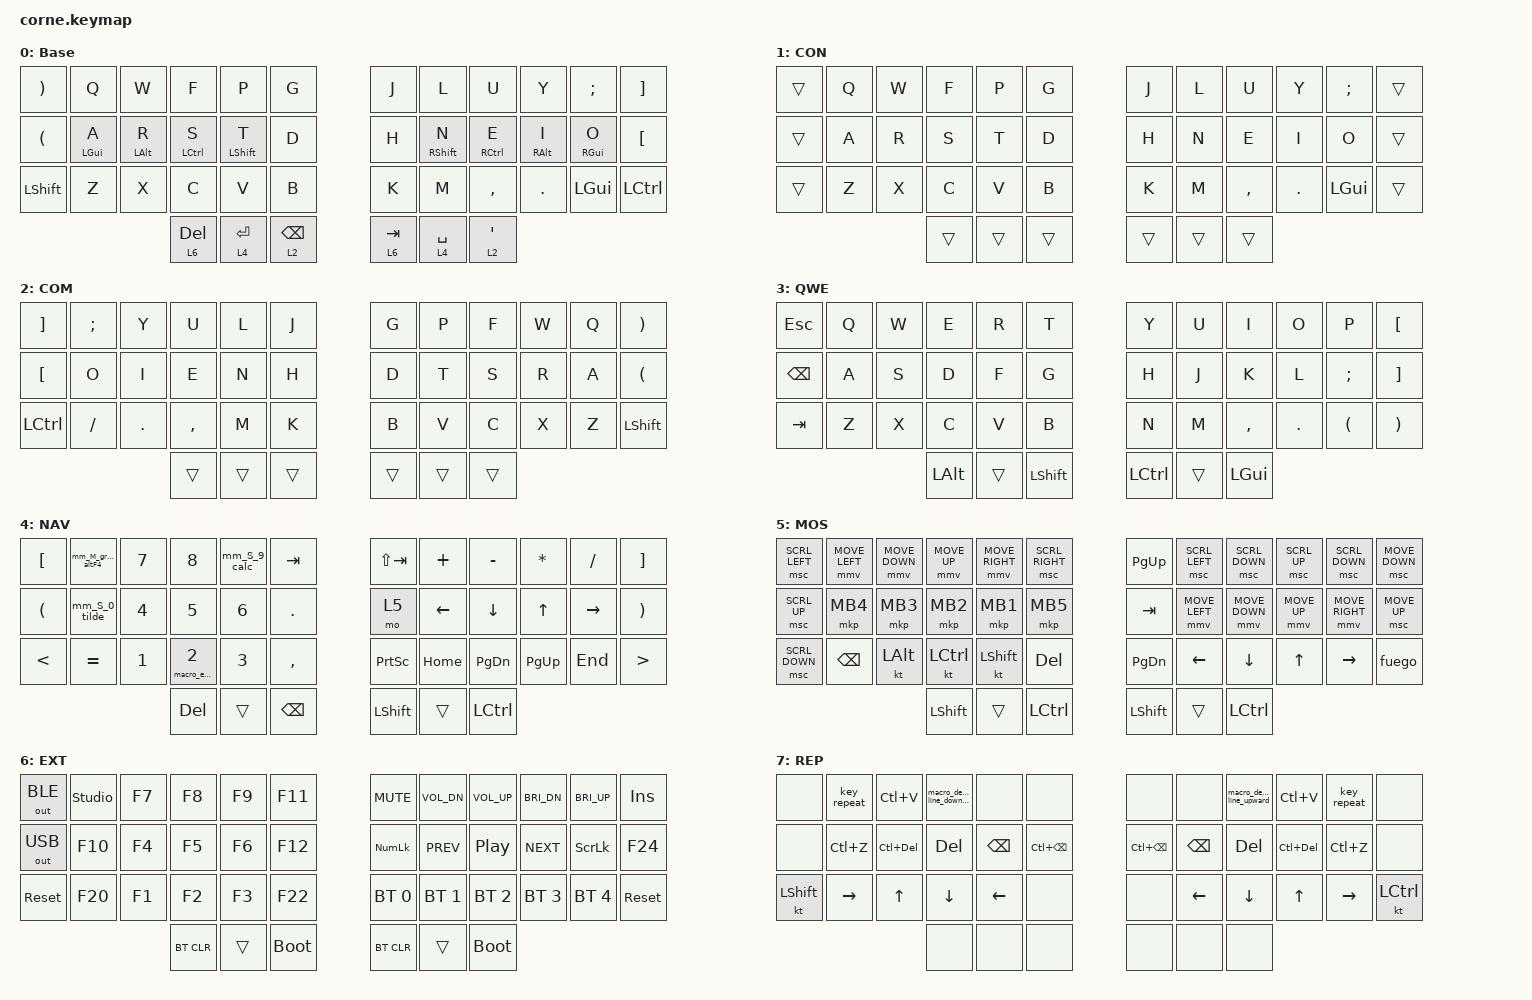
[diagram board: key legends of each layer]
/*
 * Copyright (c) 2020 The ZMK Contributors
 *
 * SPDX-License-Identifier: MIT
 */

#include "mouse.dtsi"
#include <behaviors.dtsi>
#include <dt-bindings/zmk/bt.h>
#include <dt-bindings/zmk/keys.h>
#include <dt-bindings/zmk/outputs.h>
#include <dt-bindings/led/led.h>
#include <dt-bindings/zmk/reset.h>

&caps_word { continue-list = <UNDERSCORE BACKSPACE DELETE LEFT RIGHT UP DOWN MINUS>; };

&lt {
    quick-tap-ms = <170>;
    require-prior-idle-ms = <150>;
};

&sk {
    release-after-ms = <1500>;
    quick-release;
};

&sl { release-after-ms = <500>; };

/ {
    behaviors {
        ht_kp_kp: ht_kp_kp {
            compatible = "zmk,behavior-hold-tap";
            label = "HT | KP / KP";
            bindings = <&kp>, <&kp>;

            #binding-cells = <2>;
            tapping-term-ms = <300>;
            flavor = "tap-preferred";
            quick-tap-ms = <170>;
        };

        td_S_CS: td_S_CS {
            compatible = "zmk,behavior-tap-dance";
            label = "TD | S / CS";
            #binding-cells = <0>;
            bindings = <&kp LSHFT>, <&kp LC(LSHIFT)>;
        };

        td_C_CA: td_C_CA {
            compatible = "zmk,behavior-tap-dance";
            label = "TD | C / CA";
            #binding-cells = <0>;
            bindings = <&kp LCTRL>, <&kp LC(LALT)>;
        };

        ht_capw: ht_capw {
            compatible = "zmk,behavior-hold-tap";
            label = "HT | CAPW";
            bindings = <&kp>, <&caps_word>;

            #binding-cells = <2>;
            tapping-term-ms = <170>;
        };

        ht170_kp_kp: ht170_kp_kp {
            compatible = "zmk,behavior-hold-tap";
            label = "HT170 | KP / KP";
            bindings = <&kp>, <&kp>;

            #binding-cells = <2>;
            tapping-term-ms = <170>;
            quick-tap-ms = <100>;
        };

        fuego: fuego {
            compatible = "zmk,behavior-hold-tap";
            label = "FUEGO";
            bindings = <&macro_hyperheat>, <&macro_superhot>;

            #binding-cells = <2>;
            tapping-term-ms = <500>;
        };

        email_1: email_1 {
            compatible = "zmk,behavior-hold-tap";
            label = "EMAIL_1";
            bindings = <&macro_email_dd431>, <&kp>;

            #binding-cells = <2>;
            tapping-term-ms = <200>;
        };

        ht500_kp_kp: ht500_kp_kp {
            compatible = "zmk,behavior-hold-tap";
            label = "HT500 | KP / KP";
            bindings = <&kp>, <&kp>;

            #binding-cells = <2>;
            tapping-term-ms = <500>;
            flavor = "tap-preferred";
            quick-tap-ms = <200>;
        };

        mm_A_volUp_briUp: mm_A_volUp_briUp {
            compatible = "zmk,behavior-mod-morph";
            label = "MM / ALT | VOL_UP / BRI_UP";
            bindings = <&kp C_VOL_UP>, <&kp C_BRI_UP>;

            #binding-cells = <0>;
            mods = <(MOD_LALT|MOD_RALT)>;
        };

        mm_A_volDn_briDn: mm_A_volDn_briDn {
            compatible = "zmk,behavior-mod-morph";
            label = "MM / ALT | VOLDN / BRIDN";
            bindings = <&ht_kp_kp C_MUTE C_VOL_DN>, <&kp C_BRI_DN>;

            #binding-cells = <0>;
            mods = <(MOD_LALT|MOD_RALT)>;
        };

        ht_mo_sl: ht_mo_sl {
            compatible = "zmk,behavior-hold-tap";
            label = "HT | MO / SL";
            bindings = <&mo>, <&sl>;

            #binding-cells = <2>;
            tapping-term-ms = <200>;
            flavor = "tap-preferred";
        };

        mm_S_0_tilde: mm_S_0_tilde {
            compatible = "zmk,behavior-mod-morph";
            label = "MM_S_0_TILDE";
            bindings = <&kp N0>, <&kp TILDE>;

            #binding-cells = <0>;
            mods = <(MOD_LSFT|MOD_RSFT)>;
        };

        mm_S_kp1_1: mm_S_kp1_1 {
            compatible = "zmk,behavior-mod-morph";
            label = "MM_S_KP1_1";
            bindings = <&kp KP_N1>, <&kp LS(N1)>;

            #binding-cells = <0>;
            mods = <(MOD_LSFT|MOD_RSFT)>;
        };

        mm_S_kp2_2: mm_S_kp2_2 {
            compatible = "zmk,behavior-mod-morph";
            label = "MM_S_KP2_2";
            bindings = <&kp KP_N2>, <&kp LS(N2)>;

            #binding-cells = <0>;
            mods = <(MOD_LSFT|MOD_RSFT)>;
        };

        mm_S_kp3_3: mm_S_kp3_3 {
            compatible = "zmk,behavior-mod-morph";
            label = "MM_S_KP3_3";
            bindings = <&kp KP_N3>, <&kp LS(N3)>;

            #binding-cells = <0>;
            mods = <(MOD_LSFT|MOD_RSFT)>;
        };

        mm_S_kp4_4: mm_S_kp4_4 {
            compatible = "zmk,behavior-mod-morph";
            label = "MM_S_KP4_4";
            bindings = <&kp KP_N4>, <&kp LS(N4)>;

            #binding-cells = <0>;
            mods = <(MOD_LSFT|MOD_RSFT)>;
        };

        mm_S_kp5_5: mm_S_kp5_5 {
            compatible = "zmk,behavior-mod-morph";
            label = "MM_S_KP5_5";
            bindings = <&kp KP_N5>, <&kp LS(N5)>;

            #binding-cells = <0>;
            mods = <(MOD_LSFT|MOD_RSFT)>;
        };

        mm_S_kp6_6: mm_S_kp6_6 {
            compatible = "zmk,behavior-mod-morph";
            label = "MM_S_KP6_6";
            bindings = <&kp KP_N6>, <&kp LS(N6)>;

            #binding-cells = <0>;
            mods = <(MOD_LSFT|MOD_RSFT)>;
        };

        mm_S_kp7_7: mm_S_kp7_7 {
            compatible = "zmk,behavior-mod-morph";
            label = "MM_S_KP7_7";
            bindings = <&kp KP_N7>, <&kp LS(N7)>;

            #binding-cells = <0>;
            mods = <(MOD_LSFT|MOD_RSFT)>;
        };

        mm_S_kp8_8: mm_S_kp8_8 {
            compatible = "zmk,behavior-mod-morph";
            label = "MM_S_KP8_8";
            bindings = <&kp KP_N8>, <&kp LS(N8)>;

            #binding-cells = <0>;
            mods = <(MOD_LSFT|MOD_RSFT)>;
        };

        mm_S_9_calc: mm_S_9_calc {
            compatible = "zmk,behavior-mod-morph";
            label = "MM_S_9_CALC";
            bindings = <&kp N9>, <&kp K_CALC>;

            #binding-cells = <0>;
            mods = <(MOD_LSFT|MOD_RSFT)>;
        };

        hrm_r: hrm_r {
            compatible = "zmk,behavior-hold-tap";
            label = "HRM_R";
            bindings = <&kp>, <&kp>;

            #binding-cells = <2>;
            tapping-term-ms = <1000>;
            quick-tap-ms = <80>;
            require-prior-idle-ms = <80>;
            flavor = "balanced";
            hold-trigger-on-release;
            hold-trigger-key-positions = <0 1 2 3 4 5 12 13 14 15 16 17 24 25 26 27 28 29 36 37 38 39 41 11 23 35>;
        };

        hrm_l: hrm_l {
            compatible = "zmk,behavior-hold-tap";
            label = "HRM_L";
            bindings = <&kp>, <&kp>;

            #binding-cells = <2>;
            tapping-term-ms = <1000>;
            quick-tap-ms = <80>;
            require-prior-idle-ms = <80>;
            flavor = "balanced";
            hold-trigger-on-release;
            hold-trigger-key-positions = <6 7 8 9 10 11 18 19 20 21 22 23 30 31 32 33 34 35 39 40 41 0 12 24 36 38>;
        };

        mm_S_lt_gt: mm_S_lt_gt {
            compatible = "zmk,behavior-mod-morph";
            label = "MM / SHF | LT / GT";
            bindings = <&kp LT>, <&kp GT>;

            #binding-cells = <0>;
            mods = <(MOD_LSFT|MOD_RSFT)>;
        };

        td_shf_moBaseMir: td_shf_moBaseMir {
            compatible = "zmk,behavior-tap-dance";
            label = "TD_SHF_MOBASEMIR";
            #binding-cells = <0>;
            bindings = <&kp LSHFT>, <&mo 0>;

            tapping-term-ms = <150>;
        };

        td_ctr_moBaseMir: td_ctr_moBaseMir {
            compatible = "zmk,behavior-tap-dance";
            label = "TD_CTR_MOBASEMIR";
            #binding-cells = <0>;
            bindings = <&kp LCTRL>, <&mo 0>;

            tapping-term-ms = <150>;
        };

        ht170_mo_mmbspc: ht170_mo_mmbspc {
            compatible = "zmk,behavior-hold-tap";
            label = "HT170_MO_MMBSPC";
            bindings = <&mo>, <&none>;

            #binding-cells = <2>;
            tapping-term-ms = <170>;
            quick-tap-ms = <120>;
            flavor = "hold-preferred";
        };

        td_pgdn_pgup: td_pgdn_pgup {
            compatible = "zmk,behavior-tap-dance";
            label = "TD_PGDN_PGUP";
            #binding-cells = <0>;
            bindings = <&kp PG_DN>, <&kp PG_UP>;

            tapping-term-ms = <120>;
        };

        td_pp_next_prev: td_pp_next_prev {
            compatible = "zmk,behavior-tap-dance";
            label = "TD_PP_NEXT_PREV";
            #binding-cells = <0>;
            bindings = <&kp C_PP>, <&kp C_NEXT>, <&kp C_PREV>;
        };

        mm_M_gresc_altF4: mm_M_gresc_altF4 {
            compatible = "zmk,behavior-mod-morph";
            label = "MM_M_GRESC_ALTF4";
            bindings = <&gresc>, <&kp LA(F4)>;

            #binding-cells = <0>;
            mods = <(MOD_LALT|MOD_RALT)>;
        };

        mm_S_bsp_del: mm_S_bsp_del {
            compatible = "zmk,behavior-mod-morph";
            label = "MM_S_BSP_DEL";
            bindings = <&kp BSPC>, <&kp DEL>;

            #binding-cells = <0>;
            mods = <(MOD_LSFT|MOD_RSFT)>;
        };

        ht_mo_mmLGbsp: ht_mo_mmLGbsp {
            compatible = "zmk,behavior-hold-tap";
            label = "HT_MO_MMLGBSP";
            bindings = <&mo>, <&mm_S_bsp_del>;

            #binding-cells = <2>;
            tapping-term-ms = <200>;
            quick-tap-ms = <200>;
            flavor = "hold-preferred";
        };

        ht_sl_kp: ht_sl_kp {
            compatible = "zmk,behavior-hold-tap";
            label = "HT_SL_KP";
            bindings = <&sl>, <&kp>;

            #binding-cells = <2>;
            tapping-term-ms = <200>;
            quick-tap-ms = <170>;
            flavor = "tap-preferred";
        };

        mm_S_lpar_rpar: mm_S_lpar_rpar {
            compatible = "zmk,behavior-mod-morph";
            label = "MM_S_LPAR_RPAR";
            bindings = <&kp LPAR>, <&kp RPAR>;

            #binding-cells = <0>;
            mods = <(MOD_LSFT|MOD_RSFT)>;
        };

        mm_S_lbkt_rbkt: mm_S_lbkt_rbkt {
            compatible = "zmk,behavior-mod-morph";
            label = "MM_S_LBKT_RBKT";
            bindings = <&kp LBKT>, <&kp RBKT>;

            #binding-cells = <0>;
            mods = <(MOD_LSFT|MOD_RSFT)>;
        };

        mm_S_lbrc_rbrc: mm_S_lbrc_rbrc {
            compatible = "zmk,behavior-mod-morph";
            label = "MM_S_LBRC_RBRC";
            bindings = <&kp LBRC>, <&kp RBRC>;

            #binding-cells = <0>;
            mods = <(MOD_LSFT|MOD_RSFT)>;
        };

        ht_parpair_brkpair: ht_parpair_brkpair {
            compatible = "zmk,behavior-hold-tap";
            label = "HT_PARPAIR_BRKPAIR";
            bindings = <&macro_paren_pair>, <&macro_bracket_pair>;

            #binding-cells = <2>;
            tapping-term-ms = <170>;
            flavor = "balanced";
        };

        ht_brcpair_pointypair: ht_brcpair_pointypair {
            compatible = "zmk,behavior-hold-tap";
            label = "HT_BRCPAIR_POINTYPAIR";
            bindings = <&macro_brace_pair>, <&macro_pointy_pair>;

            #binding-cells = <2>;
            tapping-term-ms = <170>;
            flavor = "balanced";
        };
    };

    macros {
        macro_superhot: superhot {
            compatible = "zmk,behavior-macro";
            #binding-cells = <0>;
            bindings = <&kp LS(I) &kp T &kp S &kp LS(D) &kp LS(M) &kp LS(D) &kp N2 &kp N5 &kp N1 &kp N0 &kp N1 &kp N5 &kp N0 &kp N7>;
            label = "SUPERHOT";
        };

        macro_hyperheat: hyperheat {
            compatible = "zmk,behavior-macro";
            #binding-cells = <0>;
            bindings = <&kp DLLR &kp LS(O) &kp LS(N) &kp D &kp LS(E) &kp LS(R) &kp LS(K) &kp LS(R) &kp AT &kp LS(F) &kp LS(T) &kp LS(F) &kp AT &kp LS(H) &kp LS(R) &kp LS(Z) &kp LS(E) &kp LS(U) &kp LS(G) &kp SPACE &kp N1 &kp N8 &kp N2>;
            label = "HYPERHEAT";
        };

        macro_email_dd431: email_dd431 {
            compatible = "zmk,behavior-macro";
            #binding-cells = <0>;
            bindings = <&kp D &kp U &kp C &kp DOT &kp D &kp A &kp O &kp DOT &kp N4 &kp N3 &kp N1 &kp AT &kp G &kp M &kp A &kp I &kp L &kp DOT &kp C &kp O &kp M>;
            label = "EMAIL_DD431";
        };

        macro_paren_pair: macro_paren_pair {
            compatible = "zmk,behavior-macro";
            #binding-cells = <0>;
            bindings = <&kp LPAR &kp RPAR &kp LEFT>;
            label = "MACRO_PAREN_PAIR";
        };

        macro_bracket_pair: macro_bracket_pair {
            compatible = "zmk,behavior-macro";
            #binding-cells = <0>;
            bindings = <&kp LBKT &kp RBKT &kp LEFT>;
            label = "MACRO_BRACKET_PAIR";
        };

        macro_brace_pair: macro_brace_pair {
            compatible = "zmk,behavior-macro";
            #binding-cells = <0>;
            bindings = <&kp LBRC &kp RBRC &kp LEFT>;
            label = "MACRO_BRACE_PAIR";
        };

        macro_pointy_pair: macro_pointy_pair {
            compatible = "zmk,behavior-macro";
            #binding-cells = <0>;
            bindings = <&kp LT &kp GT &kp LEFT>;
            label = "MACRO_POINTY_PAIR";
        };

        macro_delete_line_upward: macro_delete_line {
            compatible = "zmk,behavior-macro";
            #binding-cells = <0>;
            bindings = <&kp END &kp LS(HOME) &kp LS(UP) &kp LS(END) &kp BSPC>;
            label = "MACRO_DELETE_LINE";
        };

        macro_delete_line_downward: macro_delete_line_downward {
            compatible = "zmk,behavior-macro";
            #binding-cells = <0>;
            bindings = <&kp HOME &kp LS(END) &kp LS(DOWN) &kp LS(HOME) &kp BSPC>;
            label = "MACRO_DELETE_LINE_DOWNWARD";
        };
    };

    combos {
        compatible = "zmk,combos";

        combo_mo_mouse {
            bindings = <&mo 5>;
            key-positions = <37 40>;
            timeout-ms = <100>;
            require-prior-idle-ms = <170>;
        };

        combo_mo_deleter {
            bindings = <&mo 7>;
            key-positions = <38 39>;
            timeout-ms = <100>;
            require-prior-idle-ms = <170>;
        };

        combo_to_base {
            bindings = <&to 0>;
            key-positions = <4 3>;
            timeout-ms = <30>;
            require-prior-idle-ms = <200>;
        };

        combo_to_colemak {
            bindings = <&to 1>;
            key-positions = <4 2>;
            timeout-ms = <30>;
            require-prior-idle-ms = <200>;
        };

        combo_to_qwerty {
            bindings = <&to 3>;
            key-positions = <2 1>;
            timeout-ms = <30>;
            require-prior-idle-ms = <200>;
        };

        combo_to_mouse {
            bindings = <&to 5>;
            key-positions = <2 3>;
            timeout-ms = <30>;
            require-prior-idle-ms = <200>;
        };

        combo_to_navnum {
            bindings = <&to 4>;
            key-positions = <3 5>;
            timeout-ms = <30>;
            require-prior-idle-ms = <200>;
        };

        combo_to_extra {
            bindings = <&to 6>;
            key-positions = <5 4>;
            timeout-ms = <30>;
            require-prior-idle-ms = <200>;
        };

        combo_sk_C {
            bindings = <&sk LCTRL>;
            key-positions = <2 15>;
            timeout-ms = <30>;
            require-prior-idle-ms = <350>;
            layers = <0 1 4 5 6>;
            slow-release;
        };

        combo_sk_S {
            bindings = <&sk LSHFT>;
            key-positions = <3 16>;
            timeout-ms = <30>;
            require-prior-idle-ms = <350>;
            layers = <0 1 4 5 6>;
            slow-release;
        };

        combo_sk_M {
            bindings = <&sk LALT>;
            key-positions = <1 14>;
            timeout-ms = <30>;
            require-prior-idle-ms = <350>;
            layers = <0 1 4 5 6>;
            slow-release;
        };

        combo_sk_CS {
            bindings = <&sk LS(LCTRL)>;
            key-positions = <19 8>;
            timeout-ms = <30>;
            require-prior-idle-ms = <350>;
            layers = <0 1 4 5 6>;
            slow-release;
        };

        combo_sk_CM {
            bindings = <&sk LA(LCTRL)>;
            key-positions = <20 9>;
            timeout-ms = <30>;
            require-prior-idle-ms = <350>;
            layers = <0 1 4 5 6>;
            slow-release;
        };

        combo_sk_SM {
            bindings = <&sk LA(LSHFT)>;
            key-positions = <21 10>;
            timeout-ms = <30>;
            require-prior-idle-ms = <350>;
            layers = <0 1 4 5 6>;
            slow-release;
        };

        combo_bslh {
            bindings = <&kp BSLH>;
            key-positions = <16 29>;
            timeout-ms = <30>;
            slow-release;
            require-prior-idle-ms = <170>;
        };

        combo_under {
            bindings = <&kp UNDER>;
            key-positions = <15 28>;
            timeout-ms = <30>;
            slow-release;
            require-prior-idle-ms = <170>;
        };

        combo_lt {
            bindings = <&kp LT>;
            key-positions = <14 27>;
            timeout-ms = <30>;
            slow-release;
            require-prior-idle-ms = <170>;
        };

        combo_exclam {
            bindings = <&kp EXCL>;
            key-positions = <29 28>;
            timeout-ms = <30>;
            slow-release;
            require-prior-idle-ms = <170>;
        };

        combo_lpar {
            bindings = <&mm_S_lpar_rpar>;
            key-positions = <28 27>;
            timeout-ms = <50>;
            slow-release;
            require-prior-idle-ms = <170>;
        };

        combo_lbrc {
            bindings = <&mm_S_lbrc_rbrc>;
            key-positions = <27 26>;
            timeout-ms = <30>;
            slow-release;
            require-prior-idle-ms = <170>;
        };

        combo_lbkt {
            bindings = <&mm_S_lbkt_rbkt>;
            key-positions = <26 25>;
            timeout-ms = <30>;
            slow-release;
            require-prior-idle-ms = <170>;
        };

        combo_fslh {
            bindings = <&kp FSLH>;
            key-positions = <19 30>;
            timeout-ms = <30>;
            slow-release;
            require-prior-idle-ms = <170>;
        };

        combo_equal {
            bindings = <&kp EQUAL>;
            key-positions = <20 31>;
            timeout-ms = <30>;
            slow-release;
            require-prior-idle-ms = <170>;
        };

        combo_at {
            bindings = <&kp AT>;
            key-positions = <21 32>;
            timeout-ms = <30>;
            slow-release;
            require-prior-idle-ms = <170>;
        };

        combo_pipe {
            bindings = <&kp PIPE>;
            key-positions = <30 31>;
            timeout-ms = <30>;
            slow-release;
            require-prior-idle-ms = <170>;
        };

        combo_amps {
            bindings = <&kp AMPS>;
            key-positions = <31 32>;
            timeout-ms = <30>;
            slow-release;
            require-prior-idle-ms = <170>;
        };

        combo_hash {
            bindings = <&kp HASH>;
            key-positions = <32 33>;
            timeout-ms = <30>;
            slow-release;
            require-prior-idle-ms = <170>;
        };

        combo_qmark {
            bindings = <&kp QMARK>;
            key-positions = <33 34>;
            timeout-ms = <50>;
            slow-release;
            require-prior-idle-ms = <170>;
        };

        combo_paste {
            bindings = <&kp LC(V)>;
            key-positions = <28 27 26>;
            timeout-ms = <50>;
            slow-release;
            require-prior-idle-ms = <170>;
        };

        combo_copy {
            bindings = <&kp LC(C)>;
            key-positions = <27 26 25>;
            timeout-ms = <50>;
            slow-release;
            require-prior-idle-ms = <170>;
        };

        combo_cut {
            bindings = <&kp LC(X)>;
            key-positions = <26 25 24>;
            timeout-ms = <50>;
            slow-release;
            require-prior-idle-ms = <170>;
        };

        combo_space {
            bindings = <&kp SPACE>;
            key-positions = <16 17>;
            timeout-ms = <30>;
            require-prior-idle-ms = <200>;
        };

        combo_enter {
            bindings = <&kp ENTER>;
            key-positions = <19 18>;
            timeout-ms = <30>;
            require-prior-idle-ms = <200>;
        };

        combo_repeate_l {
            bindings = <&key_repeat>;
            key-positions = <17 4>;
            timeout-ms = <80>;
            require-prior-idle-ms = <200>;
        };

        combo_repeat_r {
            bindings = <&key_repeat>;
            key-positions = <18 7>;
            timeout-ms = <80>;
            require-prior-idle-ms = <200>;
        };

        combo_bsp {
            bindings = <&kp BSPC>;
            key-positions = <7 8>;
            timeout-ms = <50>;
            require-prior-idle-ms = <200>;
        };

        combo_del {
            bindings = <&kp DEL>;
            key-positions = <8 9>;
            timeout-ms = <50>;
            require-prior-idle-ms = <200>;
        };

        combo_C_bsp {
            bindings = <&kp LC(BSPC)>;
            key-positions = <7 6>;
            timeout-ms = <50>;
            require-prior-idle-ms = <200>;
        };

        combo_C_del {
            bindings = <&kp LC(DEL)>;
            key-positions = <10 9>;
            timeout-ms = <50>;
            require-prior-idle-ms = <200>;
        };

        combo_capsw {
            bindings = <&caps_word>;
            key-positions = <17 18>;
            timeout-ms = <80>;
            require-prior-idle-ms = <170>;
            slow-release;
        };

        combo_capsl {
            bindings = <&kp CAPS>;
            key-positions = <5 6>;
            timeout-ms = <80>;
            require-prior-idle-ms = <170>;
            slow-release;
        };
    };

    keymap {
        compatible = "zmk,keymap";
        display-name = "COL";

        base {
            bindings = <
&kp RPAR   &kp Q          &kp W          &kp F           &kp P           &kp G         &kp J      &kp L           &kp U           &kp Y          &kp SEMI       &kp RBKT
&kp LPAR   &hrm_l LGUI A  &hrm_l LALT R  &hrm_l LCTRL S  &hrm_l LSHFT T  &kp D         &kp H      &hrm_r RSHFT N  &hrm_r RCTRL E  &hrm_r RALT I  &hrm_r RGUI O  &kp LBKT
&kp LSHFT  &kp Z          &kp X          &kp C           &kp V           &kp B         &kp K      &kp M           &kp COMMA       &kp DOT        &kp LGUI       &kp LCTRL
                                         &lt 6 DEL       &lt 4 ENTER     &lt 2 BSPC    &lt 6 TAB  &lt 4 SPACE     &lt 2 SQT
            >;

            label = "Base";
        };

        colemak {
            label = "Colemak";
            display-name = "CON";
            
            bindings = <
&trans  &kp Q  &kp W  &kp F   &kp P   &kp G     &kp J   &kp L   &kp U      &kp Y    &kp SEMI  &trans
&trans  &kp A  &kp R  &kp S   &kp T   &kp D     &kp H   &kp N   &kp E      &kp I    &kp O     &trans
&trans  &kp Z  &kp X  &kp C   &kp V   &kp B     &kp K   &kp M   &kp COMMA  &kp DOT  &kp LGUI  &trans
                      &trans  &trans  &trans    &trans  &trans  &trans
            >;
        };

        colmak_mir {
            display-name = "COM";

            bindings = <
&kp RBKT   &kp SEMI  &kp Y    &kp U      &kp L   &kp J     &kp G   &kp P   &kp F   &kp W  &kp Q  &kp RPAR
&kp LBKT   &kp O     &kp I    &kp E      &kp N   &kp H     &kp D   &kp T   &kp S   &kp R  &kp A  &kp LPAR
&kp LCTRL  &kp FSLH  &kp DOT  &kp COMMA  &kp M   &kp K     &kp B   &kp V   &kp C   &kp X  &kp Z  &kp LSHFT
                              &trans     &trans  &trans    &trans  &trans  &trans
            >;

            label = "Colemak Mirrored";
        };

        qwerty {
            display-name = "QWE";

            bindings = <
&kp ESC        &kp Q  &kp W  &kp E     &kp R   &kp T        &kp Y      &kp U   &kp I      &kp O    &kp P     &kp LBKT
&kp BACKSPACE  &kp A  &kp S  &kp D     &kp F   &kp G        &kp H      &kp J   &kp K      &kp L    &kp SEMI  &kp RBKT
&kp TAB        &kp Z  &kp X  &kp C     &kp V   &kp B        &kp N      &kp M   &kp COMMA  &kp DOT  &kp LPAR  &kp RPAR
                             &kp LALT  &trans  &kp LSHFT    &kp LCTRL  &trans  &kp LGUI
            >;

            label = "Qwerty";
        };

        navnum {
            display-name = "NAV";
            
            bindings = <
&kp LBKT  &mm_M_gresc_altF4  &kp N7  &kp N8               &mm_S_9_calc  &kp TAB          &kp LS(TAB)      &kp PLUS  &kp MINUS  &kp ASTRK  &kp FSLH   &kp RBKT
&kp LPAR  &mm_S_0_tilde      &kp N4  &kp N5               &kp N6        &kp DOT          &mo 5            &kp LEFT  &kp DOWN   &kp UP     &kp RIGHT  &kp RPAR
&kp LT    &kp EQUAL          &kp N1  &email_1 0 NUMBER_2  &kp N3        &kp COMMA        &kp PRINTSCREEN  &kp HOME  &kp PG_DN  &kp PG_UP  &kp END    &kp GT
                                     &kp DEL              &trans        &kp BACKSPACE    &kp LSHFT        &trans    &kp LCTRL
            >;

            label = "Nav Num";
        };

        mouse {
            display-name = "MOS";

            bindings = <
&msc SCRL_LEFT  &mmv MOVE_LEFT  &mmv MOVE_DOWN  &mmv MOVE_UP  &mmv MOVE_RIGHT  &msc SCRL_RIGHT    &kp PG_UP   &msc SCRL_LEFT  &msc SCRL_DOWN  &msc SCRL_UP  &msc SCRL_DOWN   &msc MOVE_DOWN
&msc SCRL_UP    &mkp MB4        &mkp MB3        &mkp MB2      &mkp MB1         &mkp MB5           &kp TAB     &mmv MOVE_LEFT  &mmv MOVE_DOWN  &mmv MOVE_UP  &mmv MOVE_RIGHT  &msc MOVE_UP
&msc SCRL_DOWN  &kp BSPC        &kt LALT        &kt LCTRL     &kt LSHFT        &kp DEL            &kp PG_DN   &kp LEFT        &kp DOWN        &kp UP        &kp RIGHT        &fuego
                                                &kp LSHFT     &trans           &kp LCTRL          &kp LSHIFT  &trans          &kp LCTRL
            >;

            label = "Mouse";
        };

        extra {
            display-name = "EXT";

            bindings = <
&out OUT_BLE  &studio_unlock  &kp F7  &kp F8      &kp F9  &kp F11        &kp C_MUTE      &kp C_VOL_DN  &kp C_VOL_UP  &kp C_BRI_DN  &kp C_BRI_UP    &kp INS
&out OUT_USB  &kp F10         &kp F4  &kp F5      &kp F6  &kp F12        &kp KP_NUMLOCK  &kp C_PREV    &kp C_PP      &kp C_NEXT    &kp SCROLLLOCK  &kp F24
&sys_reset    &kp F20         &kp F1  &kp F2      &kp F3  &kp F22        &bt BT_SEL 0    &bt BT_SEL 1  &bt BT_SEL 2  &bt BT_SEL 3  &bt BT_SEL 4    &sys_reset
                                      &bt BT_CLR  &trans  &bootloader    &bt BT_CLR      &trans        &bootloader
            >;

            label = "Extra";
        };

        repeater {
            display-name = "REP";
            
            bindings = <
&none      &key_repeat  &kp LC(V)    &macro_delete_line_downward  &none     &none           &none         &none     &macro_delete_line_upward  &kp LC(V)    &key_repeat  &none
&none      &kp LC(Z)    &kp LC(DEL)  &kp DEL                      &kp BSPC  &kp LC(BSPC)    &kp LC(BSPC)  &kp BSPC  &kp DEL                    &kp LC(DEL)  &kp LC(Z)    &none
&kt LSHFT  &kp RIGHT    &kp UP       &kp DOWN                     &kp LEFT  &none           &none         &kp LEFT  &kp DOWN                   &kp UP       &kp RIGHT    &kt LCTRL
                                     &none                        &none     &none           &none         &none     &none
            >;

            label = "Repeater";
        };
    };
};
